# MINI58DE_v1 register map
File version: 1.0
Registers are 32-bit, read-write, reset 0x0 unless marked. A register's access mark holds for its fields unless they carry their own. Offsets are from the block's base; [hi:lo] are bit positions.

## SYS — SYS Register Map
Base 0x50000000
0x00 SYS_PDID ro reset not defined — Part Device Identification Number Register
  [31:0] PDID — Product Device Identification Number (Read Only). This register reflects the device part number code. Software can read this register to identify which device is used. For example, the MINI58LDE PDID code is "0x00A05800".
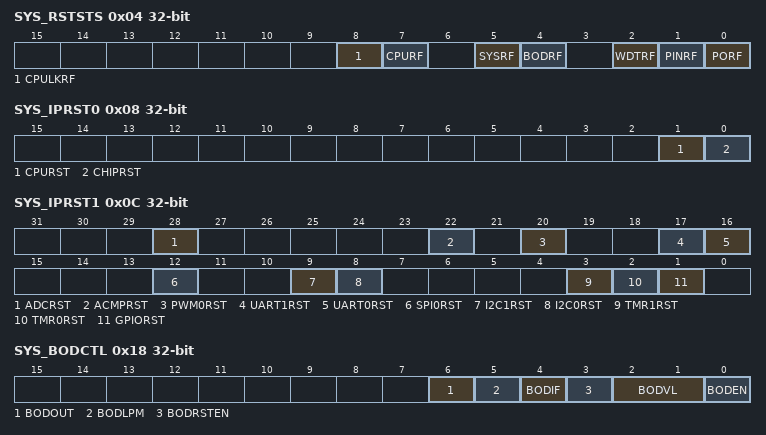
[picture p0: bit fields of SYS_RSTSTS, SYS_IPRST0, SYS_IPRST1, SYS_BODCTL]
0x04 SYS_RSTSTS (reset mask 0xFFFFFF00) — System Reset Status Register
  [8] CPULKRF — The Cortex-M0 LOCKUP Flag. Note: Software can write 1 to clear this bit to zero.
    0=No reset from Cortex-M0 LOCKUP happened; 1=The Cortex-M0 LOCKUP happened and chip is reset
  [7] CPURF — CPU Reset Flag. The CPU reset flag is set by hardware if software writes CPURST (SYS_IPRST0[1]) 1 to reset Cortex-M0 Core and Flash Memory Controller (FMC). Note: Software can write 1 to clear this bit to zero.
    0=No reset from CPU; 1=The Cortex-M0 Core and FMC are reset by software setting CPURST to 1
  [5] SYSRF — System Reset Flag. The system reset flag is set by the "Reset Signal" from the Cortex-M0 Core to indicate the previous reset source. Note: Software can write 1 to clear this bit to zero.
    0=No reset from Cortex-M0; 1=The Cortex-M0 had issued the reset signal to reset the system by writing 1 to the bit SYSRESETREQ (SCS_AIRCR[2]), Application Interrupt and Reset Control Register, address = 0xE000ED0C) in system control registers of Cortex-M0 core
  [4] BODRF — BOD Reset Flag. The BOD reset flag is set by the "Reset Signal" from the Brown-out Detector to indicate the previous reset source. Note: Software can write 1 to clear this bit to zero.
    0=No reset from BOD; 1=The BOD had issued the reset signal to reset the system
  [2] WDTRF — WDT Reset Flag. The WDT reset flag is set by the "Reset Signal" from the Watchdog Timer or Window Watchdog Timer to indicate the previous reset source. Note: Software can write 1 to clear this bit to zero.
    0=No reset from watchdog timer or window watchdog timer; 1=The watchdog timer or window watchdog timer had issued the reset signal to reset the system
  [1] PINRF — NRESET Pin Reset Flag. The nRESET pin reset flag is set by the "Reset Signal" from the nRESET pin to indicate the previous reset source. Note: Software can write 1 to clear this bit to zero.
    0=No reset from nRESET pin; 1=Pin nRESET had issued the reset signal to reset the system
  [0] PORF — POR Reset Flag. The POR reset flag is set by the "Reset Signal" from the Power-on Reset (POR) Controller or bit CHIPRST (SYS_IPRST0[0]) to indicate the previous reset source. Note: Software can write 1 to clear this bit to zero.
    0=No reset from POR or CHIPRST; 1=Power-on-Reset (POR) or CHIPRST had issued the reset signal to reset the system
0x08 SYS_IPRST0 — Peripheral Reset Control Register 0
  [1] CPURST — Processor Core One-shot Reset (Write Protect). Setting this bit will only reset the processor core and Flash Memory Controller (FMC), and this bit will automatically return to 0 after the 2 clock cycles. Note: This bit is write protected. Refer to the SYS_REGLCTL register.
    0=Processor core normal operation; 1=Processor core one-shot reset
  [0] CHIPRST — CHIP One-shot Reset (Write Protect). Setting this bit will reset the whole chip, including Processor core and all peripherals, and this bit will automatically return to 0 after the 2 clock cycles. The CHIPRST is the same as the POR reset, all the chip controllers is reset and the chip settings from flash are also reload. Note: This bit is write protected. Refer to the SYS_REGLCTL register.
    0=Chip normal operation; 1=CHIP one-shot reset
0x0C SYS_IPRST1 — Peripheral Reset Control Register 1
  [28] ADCRST — ADC Controller Reset
    0=ADC controller normal operation; 1=ADC controller reset
  [22] ACMPRST — ACMP Controller Reset
    0=ACMP controller normal operation; 1=ACMP controller reset
  [20] PWM0RST — PWM0 Controller Reset
    0=PWM0 controller normal operation; 1=PWM0 controller reset
  [17] UART1RST — UART1 Controller Reset
    0=UART1 controller normal operation; 1=UART1 controller reset
  [16] UART0RST — UART0 Controller Reset
    0=UART0 controller normal operation; 1=UART0 controller reset
  [12] SPI0RST — SPI0 Controller Reset
    0=SPI controller normal operation; 1=SPI controller reset
  [9] I2C1RST — I2C1 Controller Reset
    0=I2C1 controller normal operation; 1=I2C1 controller reset
  [8] I2C0RST — I2C0 Controller Reset
    0=I2C0 controller normal operation; 1=I2C0 controller reset
  [3] TMR1RST — Timer1 Controller Reset
    0=Timer1 controller normal operation; 1=Timer1 controller reset
  [2] TMR0RST — Timer0 Controller Reset
    0=Timer0 controller normal operation; 1=Timer0 controller reset
  [1] GPIORST — GPIO (P0~P5) Controller Reset
    0=GPIO controller normal operation; 1=GPIO controller reset
0x18 SYS_BODCTL (reset mask 0xFFFFFFF0) — Brown-out Detector Control Register
  [6] BODOUT — Brown-out Detector Output Status
    0=Brown-out Detector status output is 0, the detected voltage is higher than BODVL setting; 1=Brown-out Detector status output is 1, the detected voltage is lower than BODVL setting
  [5] BODLPM — Brown-out Detector Low Power Mode (Write Protect). Note: The BOD consumes about 100uA in normal mode, the low power mode can reduce the current to about 1/10 but slow the BOD response.
    0=BOD operate in normal mode (default); 1=BOD Low Power mode Enabled
  [4] BODIF — Brown-out Detector Interrupt Flag
    0=Brown-out Detector does not detect any voltage draft at VDD down through or up through the voltage of BODVL setting; 1=When Brown-out Detector detects the VDD is dropped through the voltage of BODVL setting or the VDD is raised up through the voltage of BODVL setting, this bit is set to 1 and the Brown-out interrupt is requested if Brown-out interrupt is enabled
  [3] BODRSTEN — Brown-out Reset Enable Bit (Write Protect). The default value is set by flash controller user configuration register CBORST(CONFIG0[20]) bit. Note: When the BOD_EN is enabled and the interrupt is asserted, the interrupt will be kept till the BOD_EN is set to 0. The interrupt for CPU can be blocked by disabling the NVIC in CPU for BOD interrupt or disable the interrupt source by disabling the BOD_EN and then re-enabling the BOD_EN function if the BOD function is required.
    0=Brown-out "INTERRUPT" function Enabled; when the Brown-out Detector function is enable and the detected voltage is lower than the threshold, then assert a signal to interrupt the Cortex-M0 CPU; 1=Brown-out "RESET" function Enabled; when the Brown-out Detector function is enable and the detected voltage is lower than the threshold then assert a signal to reset the chip
  [2:1] BODVL — Brown-out Detector Threshold Voltage Selection (Write Protect). The default value is set by flash controller user configuration register CBOV (CONFIG0[22:21]).
    1=Brown-out Detector threshold voltage is 2.7V; 2=Brown-out Detector threshold voltage is 3.7V; 3=Brown-out Detector function Disabled
  [0] BODEN — Brown-out Detector Selection Extension (Initiated Write-protected Bit)
    0=Brown-out detector threshold voltage is selected by the table defined in BODVL; 1=Brown-out detector threshold voltage is selected by the table defined as below
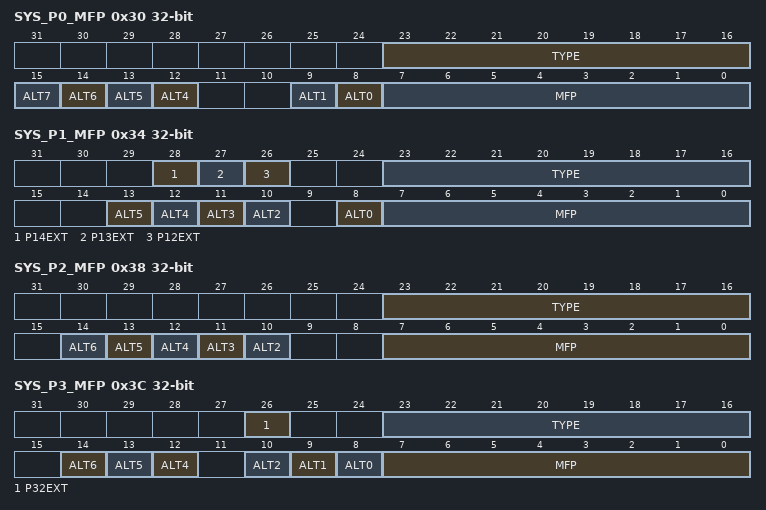
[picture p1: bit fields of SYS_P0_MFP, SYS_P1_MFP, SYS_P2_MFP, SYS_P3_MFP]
0x30 SYS_P0_MFP — P0 Multiple Function and Input Type Control Register
  [23:16] TYPE — P0[7:0] Input Schmitt Trigger Function Enable Bits
    0=P0[7:0] I/O input Schmitt Trigger function Disabled; 1=P0[7:0] I/O input Schmitt Trigger function Enabled
  [15] ALT7 — P0.7 Alternate Function Select Bit. Bits ALT[7] (SYS_P0_MFP[15]), and MFP[7] (SYS_P0_MFP[7]) determine the P0.7 function.
  [14] ALT6 — P0.6 Alternate Function Select Bit. Bits ALT[6] (SYS_P0_MFP[14]), and MFP[6] (SYS_P0_MFP[6]) determine the P0.6 function.
  [13] ALT5 — P0.5 Alternate Function Select Bit. Bits ALT[5] (SYS_P0_MFP[13]), and MFP[5] (SYS_P0_MFP[5]) determine the P0.5 function.
  [12] ALT4 — P0.4 Alternate Function Select Bit. Bits ALT[4] (SYS_P0_MFP[12]), and MFP[4] (SYS_P0_MFP[4]) determine the P0.4 function.
  [9] ALT1 — P0.1 Alternate Function Select Bit. Bits ALT[1] (SYS_P0_MFP[9]), and MFP[1] (SYS_P0_MFP[1]) determine the P0.1 function.
  [8] ALT0 — P0.0 Alternate Function Select Bit. Bits ALT[0] (SYS_P0_MFP[8]), and MFP[0] (SYS_P0_MFP[0]) determine the P0.0 function.
  [7:0] MFP — P0 Multiple Function Select Bit. The pin function of P0 depends on MFP and ALT. Refer to ALT Description for details.
0x34 SYS_P1_MFP — P1 Multiple Function and Input Type Control Register
  [28] P14EXT — P1.4 Alternate Function Selection Extension. Bits P14EXT (SYS_P1_MFP[28]), ALT[4] (SYS_P1_MFP[12]), and MFP[4] (SYS_P1_MFP[4]) determine the P1.4 function.
  [27] P13EXT — P1.3 Alternate Function Selection Extension. Bits P13EXT (SYS_P1_MFP[27]), ALT[3] (SYS_P1_MFP[11]), and MFP[3] (SYS_P1_MFP[3]) determine the P1.3 function.
  [26] P12EXT — P1.2 Alternate Function Selection Extension. Bits P12EXT (SYS_P1_MFP[26]), ALT[2] (SYS_P1_MFP[10]), and MFP[2] (SYS_P1_MFP[2]) determine the P1.2 function.
  [23:16] TYPE — P1[7:0] Input Schmitt Trigger Function Enable Bit
    0=P1[7:0] I/O input Schmitt Trigger function Disabled; 1=P1[7:0] I/O input Schmitt Trigger function Enabled
  [13] ALT5 — P1.5 Alternate Function Select Bit. Bits ALT[5] (SYS_P1_MFP[13]), and MFP[5] (SYS_P1_MFP[5]) determine the P1.5 function.
  [12] ALT4 — P1.4 Alternate Function Select Bit. Bits P14EXT (SYS_P1_MFP[28]), ALT[4] (SYS_P1_MFP[12]), and MFP[4] (SYS_P1_MFP[4]) determine the P1.4 function.
  [11] ALT3 — P1.3 Alternate Function Select Bit. Bits P13EXT (SYS_P1_MFP[27]), ALT[3] (SYS_P1_MFP[11]), and MFP[3] (SYS_P1_MFP[3]) determine the P1.3 function.
  [10] ALT2 — P1.2 Alternate Function Select Bit. Bits P12EXT (SYS_P1_MFP[26]), ALT[2] (SYS_P1_MFP[10]), and MFP[2] (SYS_P1_MFP[2]) determine the P1.2 function.
  [8] ALT0 — P1.0 Alternate Function Select Bit. Bits ALT[0] (SYS_P1_MFP[8]), and MFP[0] (SYS_P1_MFP[0]) determine the P1.0 function.
  [7:0] MFP — P1 Multiple Function Select Bit. The pin function of P1 depends on MFP and ALT. Refer to ALT Description for details.
0x38 SYS_P2_MFP — P2 Multiple Function and Input Type Control Register
  [23:16] TYPE — P2[7:0] Input Schmitt Trigger Function Enable Bits
    0=P2[7:0] I/O input Schmitt Trigger function Disabled; 1=P2[7:0] I/O input Schmitt Trigger function Enabled
  [14] ALT6 — P2.6 Alternate Function Select Bit. Bits ALT[6] (SYS_P2_MFP[14]), and MFP[6] (SYS_P2_MFP[6]) determine the P2.6 function.
  [13] ALT5 — P2.5 Alternate Function Select Bit. Bits ALT[5] (SYS_P2_MFP[13]), and MFP[5] (SYS_P2_MFP[5]) determine the P2.5 function.
  [12] ALT4 — P2.4 Alternate Function Select Bit. Bits ALT[4] (SYS_P2_MFP[12]), and MFP[4] (SYS_P2_MFP[4]) determine the P2.4 function.
  [11] ALT3 — P2.3 Alternate Function Select Bit. Bits ALT[3] (SYS_P2_MFP[11]), and MFP[3] (SYS_P2_MFP[3]) determine the P2.3 function.
  [10] ALT2 — P2.2 Alternate Function Select Bit. Bits ALT[2] (SYS_P2_MFP[10]), and MFP[2] (SYS_P2_MFP[2]) determine the P2.2 function.
  [7:0] MFP — P2 Multiple Function Select Bit. The pin function of P2 depends on MFP and ALT. Refer to ALT Description for details.
0x3C SYS_P3_MFP — P3 Multiple Function and Input Type Control Register
  [26] P32EXT — P3.2 Alternate Function Selection Extension. Bits P32EXT (SYS_P3_MFP[26]), ALT[2] (SYS_P3_MFP[10]), and MFP[2] (SYS_P3_MFP[2]) determine the P3.2 function.
  [23:16] TYPE — P3[7:0] Input Schmitt Trigger Function Enable Bits
    0=P3[7:0] I/O input Schmitt Trigger function Disabled; 1=P3[7:0] I/O input Schmitt Trigger function Enabled
  [14] ALT6 — P3.6 Alternate Function Select Bit. Bits ALT[6] (SYS_P3_MFP[14]), and MFP[6] (SYS_P3_MFP[6]) determine the P3.6 function.
  [13] ALT5 — P3.5 Alternate Function Select Bit. Bits ALT[5] (SYS_P3_MFP[13]), and MFP[5] (SYS_P3_MFP[5]) determine the P3.5 function.
  [12] ALT4 — P3.4 Alternate Function Select Bit. Bits ALT[4] (SYS_P3_MFP[12]), and MFP[4] (SYS_P3_MFP[4]) determine the P3.4 function.
  [10] ALT2 — P3.2 Alternate Function Select Bit. Bits P32EXT (SYS_P3_MFP[26]), ALT[2] (SYS_P3_MFP[10]), and MFP[2] (SYS_P3_MFP[2]) determine the P3.2 function.
  [9] ALT1 — P3.1 Alternate Function Select Bit. The pin function of P3.1 depends on P3_MFP[1] and P3_ALT[1]. Bits ALT[1] (SYS_P3_MFP[9]), and MFP[1] (SYS_P3_MFP[1]) determine the P3.1 function.
  [8] ALT0 — P3.0 Alternate Function Select Bit. Bits ALT[0] (SYS_P3_MFP[8]), and MFP[0] (SYS_P3_MFP[0]) determine the P3.0 function.
  [7:0] MFP — P3 Multiple Function Select Bits. The pin function of P3 depends on MFP and ALT. Refer to ALT Description for details.
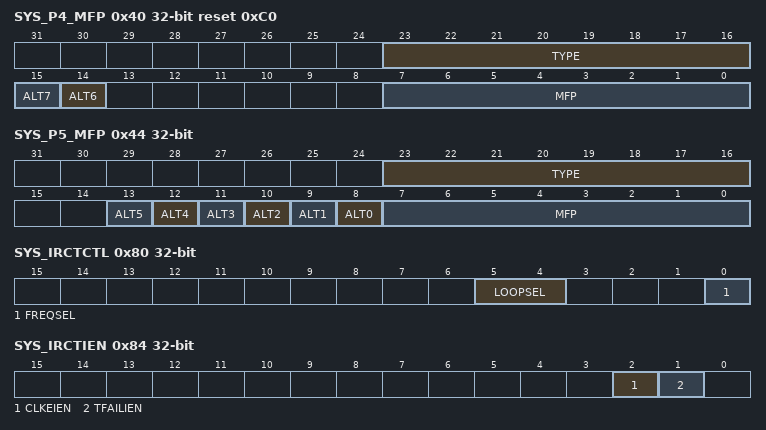
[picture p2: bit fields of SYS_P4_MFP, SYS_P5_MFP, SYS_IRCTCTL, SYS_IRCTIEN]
0x40 SYS_P4_MFP reset 0xC0 — P4 Multiple Function and Input Type Control Register
  [23:16] TYPE — P4[7:0] Input Schmitt Trigger Function Enable Bits
    0=P4[7:0] I/O input Schmitt Trigger function Disabled; 1=P4[7:0] I/O input Schmitt Trigger function Enabled
  [15] ALT7 — P4.7 Alternate Function Select Bit. Bits ALT[7] (SYS_P4_MFP[15]), and MFP[7] (SYS_P4_MFP[7]) determine the P4.7 function.
  [14] ALT6 — P4.6 Alternate Function Select Bit. Bits ALT[6] (SYS_P4_MFP[14]), and MFP[6] (SYS_P4_MFP[6]) determine the P4.6 function.
  [7:0] MFP — P4 Multiple Function Select Bits. The pin function of P4 depends on MFP and ALT. Refer to ALT Description for details.
0x44 SYS_P5_MFP — P5 Multiple Function and Input Type Control Register
  [23:16] TYPE — P5[7:0] Input Schmitt Trigger Function Enable Bits
    0=P5[7:0] I/O input Schmitt Trigger function Disabled; 1=P5[7:0] I/O input Schmitt Trigger function Enabled
  [13] ALT5 — P5.5 Alternate Function Select Bit. Bits ALT[5] (SYS_P5_MFP[13]), and MFP[5] (SYS_P5_MFP[5]) determine the P5.5 function.
  [12] ALT4 — P5.4 Alternate Function Select Bit. Bits ALT[4] (SYS_P5_MFP[12]), and MFP[4] (SYS_P5_MFP[4]) determine the P5.4 function.
  [11] ALT3 — P5.3 Alternate Function Select Bit. Bits ALT[3] (SYS_P5_MFP[11]), and MFP[3] (SYS_P5_MFP[3]) determine the P5.3 function.
  [10] ALT2 — P5.2 Alternate Function Select Bit. Bits ALT[2] (SYS_P5_MFP[10]), and MFP[2] (SYS_P5_MFP[2]) determine the P5.2 function.
  [9] ALT1 — P5.1 Alternate Function Select Bit. Bits ALT[1] (SYS_P5_MFP[9]), and MFP[1] (SYS_P5_MFP[1]) determine the P5.1 function. Note: To enable external XTAL function, the CLK_PWRCTL bit [1:0] (XTLEN), external HXT or LXT crystal oscillator control register must also be set.
  [8] ALT0 — P5.0 Alternate Function Select Bit. The pin function of P5.0 depends on MFP[0] and ALT[0]. Bits ALT[0] (SYS_P5_MFP[8]), and MFP[0] (SYS_P5_MFP[0]) determine the P5.0 function. Note: To enable external XTAL function, the CLK_PWRCTL bit [1:0] (XTLEN), external HXT or LXT crystal oscillator control register must also be set.
  [7:0] MFP — P5 Multiple Function Select Bits. The pin function of P5 depends on MFP and ALT. Refer to ALT Description for details.
0x80 SYS_IRCTCTL — HIRC Trim Control Register
  [5:4] LOOPSEL — Trim Calculation Loop. This field defines trim value calculation based on the number of LXT clock. For example, if LOOPSEL is set as "00", auto trim circuit will calculate trim value based on the average frequency difference in 4 LXT clocks. This field also defines how many times the auto trim circuit will try to update the HIRC trim value before the frequency of HIRC is locked. Once the HIRC is locked, the internal trim value update counter will be reset. If the trim value update counter reaches this limitation value and frequency of HIRC is still not locked, the auto trim operation will be disabled and FREQSEL will be cleared to 0.
    0=Trim value calculation is based on average difference in 4 LXT clock and trim retry count limitation is 64; 1=Trim value calculation is based on average difference in 8 LXT clock and trim retry count limitation is 128; 2=Trim value calculation is based on average difference in 16 LXT clock and trim retry count limitation is 256; 3=Trim value calculation is based on average difference in 32 LXT clock and trim retry count limitation is 512
  [0] FREQSEL — Trim Frequency Select Bit. This bit is to enable the HIRC auto trim. When setting this bit to 1, the HIRC auto trim function will trim HIRC to 22.1184 MHz automatically based on the LXT reference clock. During auto trim operation, if LXT clock error is detected or trim retry limitation count reached, this field will be cleared to 0 automatically.
    0=HIRC auto trim function Disabled; 1=HIRC auto trim function Enabled and HIRC trimmed to 22.1184 MHz
0x84 SYS_IRCTIEN — HIRC Trim Interrupt Enable Register
  [2] CLKEIEN — LXT Clock Error Interrupt Enable Bit. This bit controls if CPU could get an interrupt while LXT clock is inaccurate during auto trim operation. If this bit is high, and CLKERRIF (SYS_IRCTISTS[2]) is set during auto trim operation, an interrupt will be triggered to notify the LXT clock frequency is inaccurate.
    0=CLKERRIF (SYS_IRCTISTS[2]) status Disabled to trigger an interrupt to CPU; 1=CLKERRIF (SYS_IRCTISTS[2]) status Enabled to trigger an interrupt to CPU
  [1] TFAILIEN — Trim Failure Interrupt Enable Bit. This bit controls if an interrupt will be triggered while HIRC trim value update limitation count is reached and HIRC frequency is still not locked on target frequency set by FREQSEL (SYS_IRCTCTL[1:0]). If this bit is high and TFAILIF (SYS_IRCTISTS[1]) is set during auto trim operation, an interrupt will be triggered to notify that HIRC trim value update limitation count is reached.
    0=TFAILIF (SYS_IRCTISTS[1]) status Disabled to trigger an interrupt to CPU; 1=TFAILIF (SYS_IRCTISTS[1]) status Enabled to trigger an interrupt to CPU
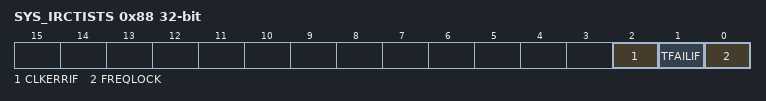
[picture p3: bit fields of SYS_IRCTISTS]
0x88 SYS_IRCTISTS — HIRC Trim Interrupt Status Register
  [2] CLKERRIF — LXT Clock Error Interrupt Status. This bit indicates that LXT clock frequency is inaccuracy. Once this bit is set, the auto trim operation stopped and FREQSEL (SYS_IRCTCTL[0]) will be cleared to 0 by hardware automatically. If this bit is set and CLKEIEN (SYS_IRCTIEN[2]) is high, an interrupt will be triggered to notify the LXT clock frequency is inaccuracy. Software can write 1 to clear this bit to 0.
    0=LXT clock frequency is accuracy; 1=LXT clock frequency is inaccuracy
  [1] TFAILIF — Trim Failure Interrupt Status. This bit indicates that HIRC trim value update limitation count reached and HIRC clock frequency still doesn't lock. Once this bit is set, the auto trim operation stopped and FREQSEL (SYS_IRCTCTL[1:0]) will be cleared to 0 by hardware automatically. If this bit is set and TFAILIEN (SYS_IRCTIEN[1]) is high, an interrupt will be triggered to notify that HIRC trim value update limitation count was reached. Software can write 1 to clear this bit to 0.
    0=Trim value update limitation count is not reached; 1=Trim value update limitation count is reached and HIRC frequency is still not locked
  [0] FREQLOCK — HIRC Frequency Lock Status. This bit indicates the HIRC frequency locked in 22.1184 MHz. This is a read only status bit and doesn't trigger any interrupt.
0x100 SYS_REGLCTL — Register Write-protection Control Register
  [7:0] REGLCTL — Register Write-protection Code. Some registers have write-protection function. Writing these registers have to disable the protected function by writing the sequence value 0x59, 0x16, 0x88 to this field. After this sequence is completed, the REGLCTL bit 0 will be set to 1 and write-protection registers can be normal write. Register Write-protection Disable Index. Please refer to 6.2.6 Register Protection.Note: The bits which are write-protected will be noted as" (Write Protect)" beside the description.
    0=Write-protection Enabled for writing protected registers. Any write to the protected register is ignored; 1=Write-protection Disabled for writing protected registers
